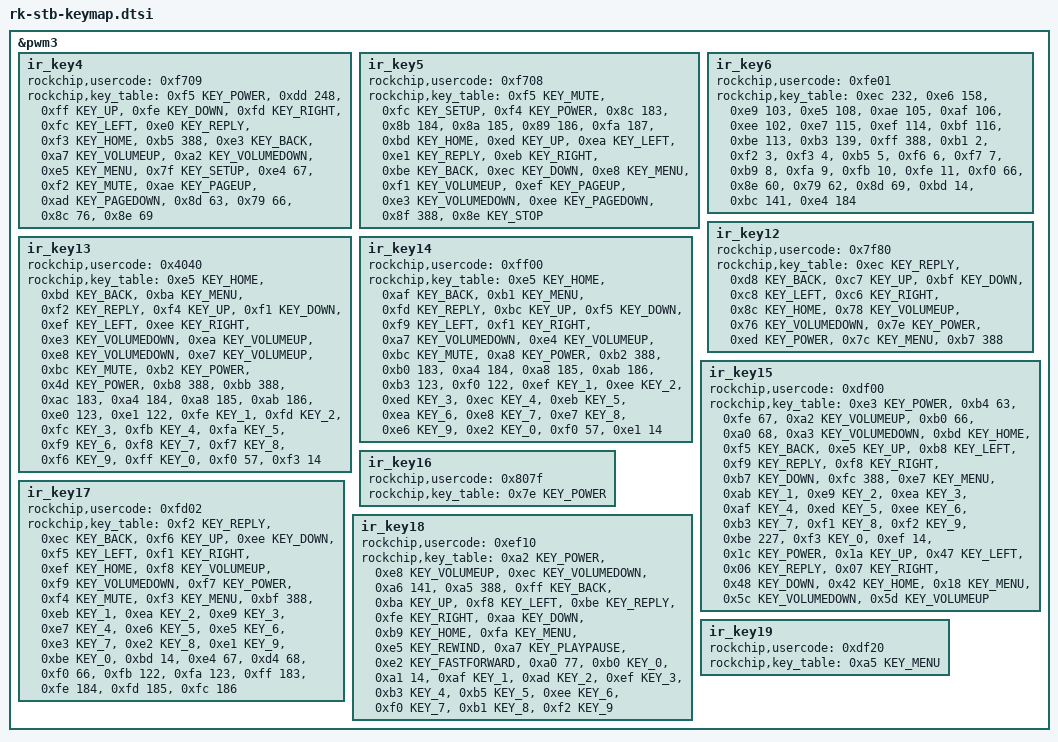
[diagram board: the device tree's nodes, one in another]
/*
 * Copyright (c) 2016 Fuzhou Rockchip Electronics Co., Ltd
 *
 * This file is dual-licensed: you can use it either under the terms
 * of the GPL or the X11 license, at your option. Note that this dual
 * licensing only applies to this file, and not this project as a
 * whole.
 *
 *  a) This library is free software; you can redistribute it and/or
 *     modify it under the terms of the GNU General Public License as
 *     published by the Free Software Foundation; either version 2 of the
 *     License, or (at your option) any later version.
 *
 *     This library is distributed in the hope that it will be useful,
 *     but WITHOUT ANY WARRANTY; without even the implied warranty of
 *     MERCHANTABILITY or FITNESS FOR A PARTICULAR PURPOSE.  See the
 *     GNU General Public License for more details.
 *
 * Or, alternatively,
 *
 *  b) Permission is hereby granted, free of charge, to any person
 *     obtaining a copy of this software and associated documentation
 *     files (the "Software"), to deal in the Software without
 *     restriction, including without limitation the rights to use,
 *     copy, modify, merge, publish, distribute, sublicense, and/or
 *     sell copies of the Software, and to permit persons to whom the
 *     Software is furnished to do so, subject to the following
 *     conditions:
 *
 *     The above copyright notice and this permission notice shall be
 *     included in all copies or substantial portions of the Software.
 *
 *     THE SOFTWARE IS PROVIDED "AS IS", WITHOUT WARRANTY OF ANY KIND,
 *     EXPRESS OR IMPLIED, INCLUDING BUT NOT LIMITED TO THE WARRANTIES
 *     OF MERCHANTABILITY, FITNESS FOR A PARTICULAR PURPOSE AND
 *     NONINFRINGEMENT. IN NO EVENT SHALL THE AUTHORS OR COPYRIGHT
 *     HOLDERS BE LIABLE FOR ANY CLAIM, DAMAGES OR OTHER LIABILITY,
 *     WHETHER IN AN ACTION OF CONTRACT, TORT OR OTHERWISE, ARISING
 *     FROM, OUT OF OR IN CONNECTION WITH THE SOFTWARE OR THE USE OR
 *     OTHER DEALINGS IN THE SOFTWARE.
 */


#include <dt-bindings/input/input.h>

&pwm3 {
	/* for IPTV */
/*	ir_key4 {
		rockchip,usercode = <0x4db2>;
		rockchip,key_table =
			<0x31	KEY_REPLY>,
			<0x3a	KEY_BACK>,
			<0x35	KEY_UP>,
			<0x2d	KEY_DOWN>,
			<0x66	KEY_LEFT>,
			<0x3e	KEY_RIGHT>,
			<0x7f	KEY_VOLUMEUP>,
			<0xfe	KEY_VOLUMEDOWN>,
			<0x23	KEY_POWER>,
			<0x63	KEY_MUTE>,
			<0x6d	KEY_1>,
			<0x6c	KEY_2>,
			<0x33	KEY_3>,
			<0x71	KEY_4>,
			<0x70	KEY_5>,
			<0x37	KEY_6>,
			<0x75	KEY_7>,
			<0x74	KEY_8>,
			<0x3b	KEY_9>,
			<0x78	KEY_0>,
			<0x73	KEY_PAGEDOWN>,
			<0x22	KEY_PAGEUP>,
			<0x72	KEY_SETUP>,
			<0x7a	KEY_CHANNEL_UP>,
			<0x79	KEY_CHANNEL_DN>,
			<0x77	KEY_HOME_PAGE>,
			<0x29	KEY_CH_CUT_BACK>,
			<0x32	KEY_DIRECT_SEEDING>,
			<0x6e	KEY_REVIEW>,
			<0x7c	KEY_ON_DEMAND>,
			<0x3c	KEY_INFO1>,
			<0x67	KEY_SOUND1>,
			<0x25	KEY_X1>,
			<0x2f	KEY_X2>,
			<0x7d	KEY_LOCAL>,
			<0x6a	KEY_PLAYPAUSE>,
			<0x0b	KEY_EQUAL>;
	};
*/
	ir_key4 {   //20230814  for AOSP VOICE  
		rockchip,usercode = <0xf709>;
		rockchip,key_table =
			<0xf5 KEY_POWER>,
			<0xdd 248>, //186>, voice
			<0xff KEY_UP>,
			<0xfe KEY_DOWN>, 
			<0xfd KEY_RIGHT>,
			<0xfc KEY_LEFT>,
			<0xe0 KEY_REPLY>,
			<0xf3 KEY_HOME>,
			<0xb5 388>, 
			<0xe3 KEY_BACK>,
			////<0x79 183>,
			////<0x8d 185>,
			<0xa7 KEY_VOLUMEUP>,
			<0xa2 KEY_VOLUMEDOWN>,
			
			<0xe5 KEY_MENU>,
			////<0xdd 231>,
			<0x7f KEY_SETUP>,
			<0xe4 67>,  //tv
			<0xf2 KEY_MUTE>,
			<0xae KEY_PAGEUP>,
			<0xad KEY_PAGEDOWN>,
			
			<0x8d 63>,  //youtube
			<0x79 66>,  //netflix
			<0x8c 76>,  //prime video
			<0x8e 69>;  //google play
	};
/*		
	ir_key5 {
		rockchip,usercode = <0xf708>;
		rockchip,key_table =
			<0xf4 KEY_POWER>,
			<0x8e KEY_ESC>,
			<0xe8 KEY_MENU>,
			<0xfa 184>,   //all 
			<0xfc KEY_SETUP>,
			
			<0xed KEY_UP>,
			<0xea KEY_LEFT>,
			<0xe1 KEY_REPLY>,
			<0xeb KEY_RIGHT>,
			<0xec KEY_DOWN>,
					
			<0xbe KEY_BACK>,
			<0x8f 388>,
			
			<0xbd KEY_HOME>,
					
			<0xf1 KEY_VOLUMEUP>,
			<0xe3 KEY_VOLUMEDOWN>,
					
			<0xf5 KEY_MUTE>,
			
			<0xef 92>,
			<0xee 93>,
			
			<0x8c 63>,	//youtube
			<0x8b 66>,	//Netflix
			<0x8a 227>,  //chrome
			<0x89 69>;  //google play
	};
*/
		//for Toplio
		ir_key5 {
		rockchip,usercode = <0xf708>;
		rockchip,key_table =
			<0xf5 KEY_MUTE>,       //mute
			<0xfc KEY_SETUP>,//141
			<0xf4 KEY_POWER>,
			<0x8c 183>,			//RED  
			<0x8b 184>,	//GREEN  
			<0x8a 185>,		//YELLOW
			<0x89 186>,		//BLUE 
			<0xfa 187>,		//APPS 			
			<0xbd KEY_HOME>,
			<0xed KEY_UP>,
			<0xea KEY_LEFT>,
			<0xe1 KEY_REPLY>,
			<0xeb KEY_RIGHT>,
			<0xbe KEY_BACK>,
			<0xec KEY_DOWN>,
			<0xe8 KEY_MENU>,
			<0xf1 KEY_VOLUMEUP>,
			<0xef KEY_PAGEUP>,		//104
			<0xe3 KEY_VOLUMEDOWN>,
			<0xee KEY_PAGEDOWN>,		//109
			<0x8f 388>,
			<0x8e KEY_STOP>;  //
	};

/*	ir_key6 {  //for gyst
		rockchip,usercode = <0xfe01>;
		rockchip,key_table =
			<0xf5 KEY_POWER>,
			<0xf0 KEY_MUTE>,
			<0xb4 183>,			//RED     
			<0xb6 185>,		//YELLOW
			<0xb7 186>,		//BLUE 
			<0xb5 184>,	//GREEN  
			<0xa1 187>,		//CHANNELUP
			<0xf1 KEY_SETUP>,//141
			<0xb1 KEY_VOLUMEUP>,
			<0xa0 188>,		//CHANNELDOWN
			<0xdc KEY_PROGRAM>,  //0x16a
			<0xb0 KEY_VOLUMEDOWN>,
			<0xf2 KEY_HOME>,
			<0xe3 KEY_BACK>,
			<0xff KEY_UP>,
			<0xfc KEY_LEFT>,
			<0xe0 KEY_REPLY>,
			<0xfd KEY_RIGHT>,
			<0xfe KEY_DOWN>,
			<0x9a KEY_MENU>,
			<0xe1 388>,
			<0xee KEY_1>,
			<0xed KEY_2>,
			<0xec KEY_3>,
			<0xeb KEY_4>,
			<0xea KEY_5>,
			<0xe9 KEY_6>,
			<0xe8 KEY_7>,
			<0xe7 KEY_8>,
			<0xe6 KEY_9>,
			<0xf9 0x166>,  //info
			<0xef KEY_0>,
			<0xa9 KEY_RECORD>;  //167
	};
*/
	/* rk new remote 1234567890 mxq gd*/
/*	ir_key6 {
		rockchip,usercode = <0xfe01>;
		rockchip,key_table =
			<0xec	KEY_REPLY>,
			<0xe6	KEY_BACK>,
			<0xe9	KEY_UP>,
			<0xe5	KEY_DOWN>,
			<0xae	KEY_LEFT>,
			<0xaf	KEY_RIGHT>,
			<0xee	KEY_HOME>,
			<0xe7	KEY_VOLUMEUP>,
			<0xef	KEY_VOLUMEDOWN>,
			<0xbf	KEY_POWER>,
			<0xbe	KEY_MUTE>,
			<0xb3	KEY_MENU>,
			<0xff	388>,
			<0xb1	KEY_1>,
			<0xf2	KEY_2>,
			<0xf3	KEY_3>,
			<0xb5	KEY_4>,
			<0xf6	KEY_5>,
			<0xf7	KEY_6>,
			<0xb9	KEY_7>,
			<0xfa	KEY_8>,
			<0xfb	KEY_9>,
			<0xfe	KEY_0>,
			//q8x
			<0xbb	KEY_F19>,  //kodi
			<0xaa KEY_REWIND>, //倒回
			<0xa5 KEY_PLAYPAUSE>,//播放/暂停
			<0xad KEY_STOP>,//停止/退出
			<0xab KEY_FASTFORWARD>,  //快进
			
			//<0xbd	KEY_EQUAL>,			
			<0xbd 14>,    // del
			<0xbc	KEY_SETUP>,//183>,
			<0xf0	184>;//KEY_LOCAL>,
			//<0x0d	KEY_DIRECT_SEEDING>,
			//<0x0c	KEY_REVIEW>,
			//<0x0b	KEY_ON_DEMAND>,
			//<0x0a	KEY_INFO1>,
			//<0x0e	KEY_CH_CUT_BACK>;
	};
	*/
		ir_key6 {
		  rockchip,usercode = <0xfe01>;
		  rockchip,key_table =
		   <0xec 232>,
		   <0xe6 158>,
		   <0xe9 103>,
		   <0xe5 108>,
		   <0xae 105>,
		   <0xaf 106>,
		   <0xee 102>,
		   <0xe7 115>,
		   <0xef 114>,
		   <0xbf 116>,
		   <0xbe 113>,
		   <0xb3 139>,
		   <0xff 388>,
		   <0xb1 2>,
		   <0xf2 3>,
		   <0xf3 4>,
		   <0xb5 5>,
		   <0xf6 6>,
		   <0xf7 7>,
		   <0xb9 8>,
		   <0xfa 9>,
		   <0xfb 10>,
		   <0xfe 11>,


		   <0xf0 66>,
		   <0x8e 60>,
		   <0x79 62>,
		   <0x8d 69>,
		   <0xbd 14>,

		   <0xbc 141>,
		   <0xe4 184>;
		 };
 
/*
	ir_key6 {
		rockchip,usercode = <0xfe01>;
		rockchip,key_table =
			<0xec	KEY_REPLY>,
			<0xe6	KEY_BACK>,
			<0xe9	KEY_UP>,
			<0xe5	KEY_DOWN>,
			<0xae	KEY_LEFT>,
			<0xaf	KEY_RIGHT>,
			<0xe7	KEY_HOME>,
			<0xee	KEY_VOLUMEUP>,
			<0xb3	KEY_VOLUMEDOWN>,
			<0xbf	KEY_POWER>,
			<0xa2	KEY_POWER>,
			<0xbe	KEY_MUTE>,
			<0xef KEY_MENU>,
			<0xb2	150>,  //Browser
			<0xff	388>,
			<0xb1	KEY_1>,
			<0xf2	KEY_2>,
			<0xf3	KEY_3>,
			<0xb5	KEY_4>,
			<0xf6	KEY_5>,
			<0xf7	KEY_6>,
			<0xb9	KEY_7>,
			<0xfa	KEY_8>,
			<0xfb	KEY_9>,
			<0xfe	KEY_0>,
			//<0xbd	KEY_EQUAL>,			
			<0xbd 14>,    // del
			<0xbc	KEY_SETUP>,
			<0xf0	KEY_LOCAL>,
			<0x0d	KEY_DIRECT_SEEDING>,
			<0x0c	KEY_REVIEW>,
			<0x0b	KEY_ON_DEMAND>,
			<0x0a	KEY_INFO1>,
			<0x0e	KEY_CH_CUT_BACK>;
	};
*/
	/* for IPTV gd */
/*	ir_key7 {
		rockchip,usercode = <0x4cb3>;
		rockchip,key_table =
			<0x31	KEY_REPLY>,
			<0x3a	KEY_BACK>,
			<0x35	KEY_UP>,
			<0x2d	KEY_DOWN>,
			<0x66	KEY_LEFT>,
			<0x3e	KEY_RIGHT>,
			<0x7f	KEY_VOLUMEUP>,
			<0x7e	KEY_VOLUMEDOWN>,
			<0x23	KEY_POWER>,
			<0x63	KEY_MUTE>,
			<0x6d	KEY_1>,
			<0x6c	KEY_2>,
			<0x33	KEY_3>,
			<0x71	KEY_4>,
			<0x70	KEY_5>,
			<0x37	KEY_6>,
			<0x75	KEY_7>,
			<0x74	KEY_8>,
			<0x3b	KEY_9>,
			<0x78	KEY_0>,
			<0x73	KEY_PAGEDOWN>,
			<0x22	KEY_PAGEUP>,
			<0x72	KEY_SETUP>,
			//<0x7a	KEY_CHANNEL_UP>,
			//<0x79	KEY_CHANNEL_DN>,
			//<0x77	KEY_HOME_PAGE>,
			<0x29	KEY_CH_CUT_BACK>,
			<0x32	KEY_DIRECT_SEEDING>,
			<0x6e	KEY_REVIEW>,
			<0x7c	KEY_ON_DEMAND>,
			<0x3c	KEY_INFO1>,
			<0x67	KEY_SOUND1>,
			<0x25	KEY_X1>,
			<0x2f	KEY_X2>,
			<0x7d	KEY_LOCAL>,
			<0x6a	KEY_PLAYPAUSE>,
			<0x0b	KEY_EQUAL>;
	};
*/
	/* for CMCC */
/*	ir_key8 {
		rockchip,usercode = <0xdd22>;
		rockchip,key_table =
			<0x31	KEY_REPLY>,
			<0x6a	KEY_BACK>,
			<0x35	KEY_UP>,
			<0x2d	KEY_DOWN>,
			<0x66	KEY_LEFT>,
			<0x3e	KEY_RIGHT>,
			<0x7f	KEY_VOLUMEUP>,
			<0x7e	KEY_VOLUMEDOWN>,
			<0x23	KEY_POWER>,
			<0x63	KEY_MUTE>,
			<0x6d	KEY_1>,
			<0x6c	KEY_2>,
			<0x33	KEY_3>,
			<0x71	KEY_4>,
			<0x70	KEY_5>,
			<0x37	KEY_6>,
			<0x75	KEY_7>,
			<0x74	KEY_8>,
			<0x3b	KEY_9>,
			<0x78	KEY_0>,
			<0x73	KEY_PAGEDOWN>,
			<0x22	KEY_PAGEUP>,
			<0x72	KEY_SETUP>,
			<0x7a	KEY_CHANNEL_UP>,
			<0x79	KEY_CHANNEL_DN>,
			<0x77	KEY_HOME_PAGE>,
			<0x2f	KEY_CH_CUT_BACK>,
			<0x32	KEY_DIRECT_SEEDING>,
			<0x6e	KEY_REVIEW>,
			<0x7c	KEY_ON_DEMAND>,
			<0x3c	KEY_INFO1>,
			<0x3a	KEY_HELP>,
			<0x67	KEY_SOUND1>,
			<0x25	KEY_X2>,
			<0x7d	KEY_MENU>,
			<0x3f	KEY_EQUAL>,
			<0x29	388>,
			<0x26	KEY_PLAYPAUSE>,
			<0x76	401>,
			<0x7b	400>,
			<0x69	66>;
	};
*/
	/* for BJLT IPTV */
/*	ir_key9 {
		rockchip,usercode = <0x3bc4>;
		rockchip,key_table =
			<0x81	KEY_REPLY>,
			<0x80	KEY_BACK>,
			<0x85	KEY_UP>,
			<0x87	KEY_DOWN>,
			<0x84	KEY_LEFT>,
			<0x86	KEY_RIGHT>,
			<0x99	KEY_VOLUMEUP>,
			<0x9a	KEY_VOLUMEDOWN>,
			<0x96	KEY_POWER>,
			<0x9b	KEY_MUTE>,
			<0x89	KEY_1>,
			<0x8a	KEY_2>,
			<0x8b	KEY_3>,
			<0x8c	KEY_4>,
			<0x8d	KEY_5>,
			<0x8e	KEY_6>,
			<0x8f	KEY_7>,
			<0x90	KEY_8>,
			<0x91	KEY_9>,
			<0x88	KEY_0>,
			<0x83	KEY_PAGEDOWN>,
			<0x82	KEY_PAGEUP>,
			<0x95	KEY_SETUP>,
			<0x97	KEY_CHANNEL_UP>,
			<0x98	KEY_CHANNEL_DN>,
			<0xc6	KEY_LOCAL>,
			<0xd6	KEY_HOME_PAGE>,
			<0xd7	KEY_TRACK>,
			<0xcc	KEY_CH_CUT_BACK>,
			<0xc3	KEY_INTERX>,
			<0xd1	KEY_DIRECT_SEEDING>,
			<0xd2	KEY_REVIEW>,
			<0xd3	KEY_ON_DEMAND>,
			<0xd4	KEY_INFO1>,
			<0xc7	KEY_DIRECT_SEEDING>,
			<0xc8	KEY_REVIEW>,
			<0xc9	KEY_ON_DEMAND>,
			<0xca	KEY_INFO1>,
			<0xcd	KEY_FAVORITE>,
			<0xce	KEY_CHANNEL_POS>,
			<0xcf	KEY_HELP>,
			<0xd0	KEY_EVENT>,
			<0x9c	KEY_SOUND1>,
			<0x93	KEY_X1>,
			<0x92	KEY_X2>,
			<0xc0	KEY_END>,
			<0xc1	KEY_GO_BEGINNING>,
			<0x9d	KEY_PLAYPAUSE>,
			<0xc4	KEY_STOP>,
			<0x94	KEY_EQUAL>,
			<0x9e	KEY_YELLOW>,
			<0x9f	KEY_BLUE>,
			<0xcb	KEY_APPLICATION>,
			<0xc5	KEY_POS>;
	};
*/
	/* IPTV_AHDX FibeHome */
/*	ir_key10 {
			rockchip,usercode = <0xee11>;
			rockchip,key_table =
			<0xea	KEY_REPLY>,
			<0xed	KEY_BACK>,
			<0xeb	KEY_UP>,
			<0xe9	KEY_DOWN>,
			<0xe2	KEY_LEFT>,
			<0xee	KEY_RIGHT>,
			<0xb4	KEY_VOLUMEUP>,
			<0xe3	KEY_VOLUMEDOWN>,
			<0xbc	KEY_POWER>,
			<0xb8	KEY_MUTE>,
			<0xa2	KEY_MENU>, //bookmark
			<0xab	KEY_POS>, //locate
			<0xbd	KEY_1>,
			<0xbe	KEY_2>,
			<0xbf	KEY_3>,
			<0xb9	KEY_4>,
			<0xba	KEY_5>,
			<0xbb	KEY_6>,
			<0xb5	KEY_7>,
			<0xb6	KEY_8>,
			<0xb7	KEY_9>,
			<0xb2	KEY_0>,
			<0xef	KEY_PAGEDOWN>,
			<0xe7	KEY_PAGEUP>,
			<0xaa	KEY_SETUP>,
			<0xae	KEY_CHANNEL_UP>,
			<0xaf	KEY_CHANNEL_DN>,
			<0xe1	KEY_HOME_PAGE>,
			<0xa0	KEY_DIRECT_SEEDING>,
			<0xa4	KEY_REVIEW>,
			<0xa8	KEY_ON_DEMAND>,
			<0xac	KEY_INFO1>,
			<0xd5	KEY_SOUND1>,
			<0xa6	KEY_EQUAL>,
			<0xe4	KEY_PLAYPAUSE>,
			<0xe5	KEY_X2>, //inputmethod
			<0xe6	KEY_X1>; //Soft input
	};
*/
	/*for IPTV hblt*/
/*	ir_key11 {
		rockchip,usercode = <0xc43b>;
		rockchip,key_table =
			<0x7e	KEY_REPLY>,  //确定/播放/暂停
			<0x7f	KEY_BACK>,  //返回/停止
			<0x7a	KEY_UP>,   //上/音量+
			<0x78	KEY_DOWN>,  //下/音量-
			<0x7b	KEY_LEFT>,//左/快退
			<0x79	KEY_RIGHT>,//右/快进
			<0x66	KEY_VOLUMEUP>,
			<0x65	KEY_VOLUMEDOWN>,
			<0x69	KEY_POWER>,//电源
			<0x64	KEY_MUTE>,//静音
			<0x76	KEY_1>,
			<0x75	KEY_2>,
			<0x74	KEY_3>,
			<0x73	KEY_4>,
			<0x72	KEY_5>,
			<0x71	KEY_6>,
			<0x70	KEY_7>,
			<0x6f	KEY_8>,
			<0x6e	KEY_9>,
			<0x77	KEY_0>,//0/space
			<0x7c	KEY_PAGEDOWN>,
			<0x7d	KEY_PAGEUP>,
			<0x6a	KEY_SETUP>,//设置
			<0x68	KEY_CHANNEL_UP>,//频道加
			<0x67	KEY_CHANNEL_DN>,//频道减
			<0x39	KEY_PORTAL>,  //跳转至IPTV EPG
			<0x29	KEY_HOME_PAGE>,//主页
			<0x33	KEY_CH_CUT_BACK>,//切换
			<0x2d	KEY_REVIEW>,  //点播
			<0x2c	KEY_ON_DEMAND>,//回看
			<0x2b	KEY_INFO1>,//通讯
			<0x2e	KEY_DIRECT_SEEDING>,//快捷键（红色)
			<0x2d	KEY_REVIEW>,//快捷键（绿色)
			<0x2c	KEY_ON_DEMAND>,//快捷键（黄色）
			<0x2b	KEY_INFO1>,//快捷键（蓝色)
			<0x63	KEY_SOUND1>,//声道
			<0x6c	KEY_X1>, //软键盘
			<0x6d	KEY_X2>,//输入法
			<0x62	KEY_PLAYPAUSE>,//播放/暂停
			<0x6b	KEY_EQUAL>,//删除
			<0x61	KEY_FASTFORWARD>,//快进
			<0x60	KEY_REWIND>,  //快退
			<0x3b	KEY_STOP>; //停止
	};
*/	
	ir_key12{
		rockchip,usercode = <0x7f80>;
		rockchip,key_table =
			<0xec	KEY_REPLY>,
			<0xd8	KEY_BACK>,
			<0xc7	KEY_UP>,
			<0xbf	KEY_DOWN>,
			<0xc8	KEY_LEFT>,
			<0xc6	KEY_RIGHT>,
			<0x8c	KEY_HOME>,
			<0x78	KEY_VOLUMEUP>,
			<0x76	KEY_VOLUMEDOWN>,
			<0x7e	KEY_POWER>,
			<0xed	KEY_POWER>,  //20171123 
			<0x7c	KEY_MENU>,
			<0xb7	388>;
	};

	ir_key13{
		rockchip,usercode = <0x4040>;
		rockchip,key_table =
			    <0xe5 KEY_HOME>,
			    <0xbd KEY_BACK>, 		// back
			    <0xba KEY_MENU>,			// menu
			    <0xf2 KEY_REPLY>,		// ok
			    <0xf4 KEY_UP>,	
			    <0xf1 KEY_DOWN>,
			    <0xef KEY_LEFT>,
			    <0xee KEY_RIGHT>,
			    <0xe3 KEY_VOLUMEDOWN>,
			    <0xea KEY_VOLUMEUP>,
			    <0xe8 KEY_VOLUMEDOWN>,
			    <0xe7 KEY_VOLUMEUP>,
			    <0xbc KEY_MUTE>,       //mute
			    <0xb2 KEY_POWER>,     //power (RED)
			    <0x4d KEY_POWER>,     //power (for 2.4g)
				//mouse switch
			    <0xb8 388>,           //1
			    <0xbb 388>,           //1
				//function
			    <0xac 183>,	// key red
			    <0xa4 184>,	// key green
			    <0xa8 185>,	// key yellow
			    <0xab 186>,	// key blue
			    <0xe0 123>,	// MEDIA_NEXT
			    <0xe1 122>,	// MEDIA_PREVIOUS
				//digital
			    <0xfe KEY_1>,	// Digit 1
			    <0xfd KEY_2>,	// Digit 2
			    <0xfc KEY_3>,	// Digit 3
			    <0xfb KEY_4>,	// Digit 4
			    <0xfa KEY_5>,	// Digit 5
			    <0xf9 KEY_6>,	// Digit 6
			    <0xf8 KEY_7>,	// Digit 7
			    <0xf7 KEY_8>,	// Digit 8
			    <0xf6 KEY_9>,	// Digit 9
			    <0xff KEY_0>,	// Digit 0
			    <0xf0 57>,		// for all
			    <0xf3 14>;     // del
			    
	};
	ir_key14{
		rockchip,usercode = <0xff00>;  //iconbit
		rockchip,key_table =
			    <0xe5 KEY_HOME>,
			    <0xaf KEY_BACK>, 		// back
			    <0xb1 KEY_MENU>,			// menu
			    <0xfd KEY_REPLY>,		// ok
			    <0xbc KEY_UP>,	
			    <0xf5 KEY_DOWN>,
			    <0xf9 KEY_LEFT>,
			    <0xf1 KEY_RIGHT>,
			    <0xa7 KEY_VOLUMEDOWN>,
			    <0xe4 KEY_VOLUMEUP>,
			    <0xbc KEY_MUTE>,       //mute
			    <0xa8 KEY_POWER>,     //power (RED)
				//mouse switch
			    <0xb2 388>,           //1
				//function
			    <0xb0 183>,	// key red - for setting
			    <0xa4 184>,	// key green
			    <0xa8 185>,	// key yellow
			    <0xab 186>,	// key blue
			    <0xb3 123>,	// MEDIA_NEXT
			    <0xf0 122>,	// MEDIA_PREVIOUS
				//digital
			    <0xef KEY_1>,	// Digit 1
			    <0xee KEY_2>,	// Digit 2
			    <0xed KEY_3>,	// Digit 3
			    <0xec KEY_4>,	// Digit 4
			    <0xeb KEY_5>,	// Digit 5
			    //<0xeb KEY_POWER>,     //power (RED)  for rbox r10
			    <0xea KEY_6>,	// Digit 6
			    <0xe8 KEY_7>,	// Digit 7
			    <0xe7 KEY_8>,	// Digit 8
			    <0xe6 KEY_9>,	// Digit 9
			    <0xe2 KEY_0>,	// Digit 0
			    <0xf0 57>,		// for all
			    <0xe1 14>;     // del
	};
	/*
	ir_key14 {
		rockchip,usercode = <0x0707>;
		rockchip,key_table =
			<0xfd KEY_POWER>,			
			<0xc1 KEY_PLAYPAUSE>,
			<0xec 388>,			
			<0x9f KEY_UP>,
			<0x9a KEY_LEFT>,
			<0x97 KEY_REPLY>,
			<0x9d KEY_RIGHT>,
			<0x9e KEY_DOWN>,			
			<0xd2 KEY_HOME>,
			<0xe5 KEY_MENU>,			
			<0xed KEY_REWIND>, //倒回
			<0xef KEY_FASTFORWARD>,  //快进			
			<0x77 231>,			
			<0xf8 KEY_VOLUMEUP>,
			<0xf4 KEY_VOLUMEDOWN>,			
			<0xa3 14>,
			<0xf0 KEY_MUTE>;
	};
	*/
/*	
	ir_key14{ //TRS2044
		rockchip,usercode = <0xff00>;  //iconbit
		rockchip,key_table =
			    <0xa8 KEY_POWER>;     // del
	};
	*/
	ir_key15{
		rockchip,usercode = <0xdf00>;
		rockchip,key_table =
			<0xe3 KEY_POWER>,
			<0xb4 63>,	//youtube
			<0xfe 67>,	//Media Center
			<0xa2 KEY_VOLUMEUP>,
			<0xb0 66>,	//Netflix
			<0xa0 68>,	//SetupWizard
			<0xa3 KEY_VOLUMEDOWN>,
			
			<0xbd KEY_HOME>,
			<0xf5 KEY_BACK>,
			
			<0xe5 KEY_UP>,    
			<0xb8 KEY_LEFT>,  
			<0xf9 KEY_REPLY>, 
			<0xf8 KEY_RIGHT>, 
			<0xb7 KEY_DOWN>,  
			<0xfc 388>,
			<0xe7 KEY_MENU>,
			
			<0xab KEY_1>, 
			<0xe9 KEY_2>, 
			<0xea KEY_3>, 
			<0xaf KEY_4>, 
			<0xed KEY_5>, 
			<0xee KEY_6>, 
			<0xb3 KEY_7>, 
			<0xf1 KEY_8>, 
			<0xf2 KEY_9>,
			<0xbe 227>,  //Fn
			<0xf3 KEY_0>,
			<0xef 14>,
			
		//for bt remote
			<0x1c KEY_POWER>,
			<0x1a KEY_UP>,
			<0x47 KEY_LEFT>,
			<0x06 KEY_REPLY>,
			<0x07 KEY_RIGHT>,
			<0x48 KEY_DOWN>,
			<0x42 KEY_HOME>,
			<0x18 KEY_MENU>,
		//	<0x0a KEY_BACK>,
			<0x5c KEY_VOLUMEDOWN>,
			<0x5d KEY_VOLUMEUP>;		
		//end
	};
		
	ir_key16{
		rockchip,usercode = <0x807f>;
		rockchip,key_table =
			<0x7e	KEY_POWER>;
	};

	ir_key17 {
		rockchip,usercode = <0xfd02>;
		rockchip,key_table =
			<0xf2	KEY_REPLY>,
			<0xec	KEY_BACK>,
			<0xf6	KEY_UP>,
			<0xee	KEY_DOWN>,
			<0xf5	KEY_LEFT>,
			<0xf1	KEY_RIGHT>,
			<0xef	KEY_HOME>,
			<0xf8	KEY_VOLUMEUP>,
			<0xf9	KEY_VOLUMEDOWN>,
			<0xf7	KEY_POWER>,
			<0xf4	KEY_MUTE>,
			<0xf3	KEY_MENU>,
			<0xbf	388>,
			<0xeb 	KEY_1>,
			<0xea 	KEY_2>,
			<0xe9 	KEY_3>,
			<0xe7 	KEY_4>,
			<0xe6 	KEY_5>,
			<0xe5 	KEY_6>,
			<0xe3 	KEY_7>,
			<0xe2 	KEY_8>,
			<0xe1 	KEY_9>,
			<0xbe	KEY_0>,
			//<0xbd	KEY_EQUAL>,			
			<0xbd 14>,    // del	
			<0xe4 67>,    // KEY_F7 KEY_TV
			<0xd4 68>,    // KEY_F8 KEY_VIDEO
			//<0xf0 0x166>,    // info
			<0xf0 66>,    // f8
			<0xfb	122>, //MEDIA_PREVIOUS
			<0xfa	123>, //MEDIA_NEXT
			//<0xff	59>, //PROG_RED
			//<0xfe	60>, //PROG_GREEN
			//<0xfd	61>, //PROG_YELLOW
			//<0xfc	62>; //PROG_BLUE
			<0xff	183>, //PROG_RED
			<0xfe	184>, //PROG_GREEN
			<0xfd	185>, //PROG_YELLOW
			<0xfc	186>; //PROG_BLUE
	};

	ir_key18 {
		rockchip,usercode = <0xef10>;
		rockchip,key_table =
			<0xa2 KEY_POWER>,
			<0xe8 KEY_VOLUMEUP>,
			<0xec KEY_VOLUMEDOWN>,
			<0xa6 141>,//KEY_SETUP>,
			<0xa5 388>,
			<0xff KEY_BACK>,
			<0xba KEY_UP>,
			<0xf8 KEY_LEFT>,
			<0xbe KEY_REPLY>,
			<0xfe KEY_RIGHT>,
			<0xaa KEY_DOWN>,
			<0xb9 KEY_HOME>,
			<0xfa KEY_MENU>,
			<0xe5 KEY_REWIND>, //倒回
			<0xa7 KEY_PLAYPAUSE>,//播放/暂停
			<0xe2 KEY_FASTFORWARD>,  //快进
			<0xa0 77>,  //@
			<0xb0 KEY_0>,
			<0xa1 14>,
			<0xaf KEY_1>,
			<0xad KEY_2>,
			<0xef KEY_3>,
			<0xb3 KEY_4>,
			<0xb5 KEY_5>,
			<0xee KEY_6>,
			<0xf0 KEY_7>,
			<0xb1 KEY_8>,
			<0xf2	KEY_9>;
	};

/*	
	ir_key19 {
		rockchip,usercode = <0x4db2>;
		rockchip,key_table =
			<0x63 KEY_MUTE>,       //mute
			//<0x72 183>,//KEY_SETUP>,		141
			<0x72 KEY_SETUP>,//141
			<0x23 KEY_POWER>,
			<0x7b 183>,			//RED  
			<0x76 184>,	//GREEN  
			<0x26 185>,		//YELLOW
			<0x69 186>,		//BLUE  
			<0x77 KEY_HOME>,
			<0x35 KEY_UP>,
			<0x6a KEY_PLAYPAUSE>,
			<0x66 KEY_LEFT>,
			<0x31 KEY_REPLY>,
			<0x3e KEY_RIGHT>,
			<0x3a KEY_BACK>,
			<0x2d KEY_DOWN>,
			<0x65 KEY_MENU>,
			<0x7f KEY_VOLUMEUP>,
			<0x22 KEY_PAGEUP>,		//104
			<0x7a 187>,		//CHANNELUP
			<0x7e KEY_VOLUMEDOWN>,
			<0x73 KEY_PAGEDOWN>,		//109
			<0x79 188>,		//CHANNELDOWN
			<0x6d KEY_1>,
			<0x6c KEY_2>,
			<0x33 KEY_3>,
			<0x71 KEY_4>,
			<0x70 KEY_5>,
			<0x37 KEY_6>,
			<0x75 KEY_7>,
			<0x74 KEY_8>,
			<0x3b KEY_9>,
			<0x25 14>,
			<0x78 KEY_0>,
			<0x2f KEY_LANGUAGE>; //0x170
	};*/
/*
	ir_key19 {   //20230603  only for Gocast test  
		rockchip,usercode = <0xdf20>;
		rockchip,key_table =
			<0xa5 180>,
			<0xa9 181>,
			<0xae 182>,
			<0xef KEY_VOLUMEDOWN>, 
			<0xe7 KEY_VOLUMEUP>;
	};
*/

	ir_key19 {
		rockchip,usercode = <0xdf20>;
		rockchip,key_table =
			<0xa5 KEY_MENU>; //0x170
	};
};

